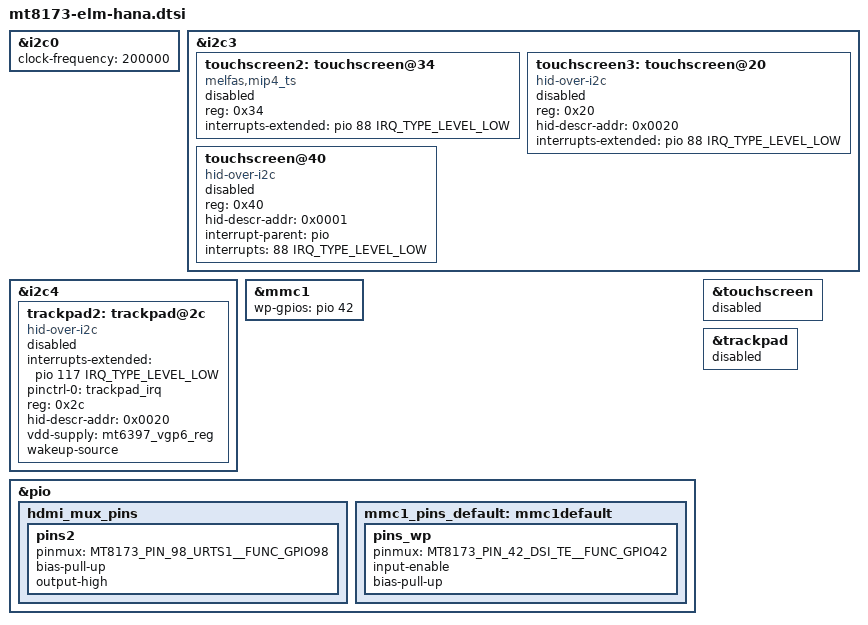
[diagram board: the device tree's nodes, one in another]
// SPDX-License-Identifier: GPL-2.0-only
/*
 * Copyright 2016 MediaTek Inc.
 */

#include "mt8173-elm.dtsi"

&i2c0 {
	clock-frequency = <200000>;
};

&i2c3 {
	touchscreen2: touchscreen@34 {
		compatible = "melfas,mip4_ts";
		reg = <0x34>;
		interrupts-extended = <&pio 88 IRQ_TYPE_LEVEL_LOW>;
		status = "fail-needs-probe";
	};

	/*
	 * Lenovo 100e Chromebook 2nd Gen (MTK) and Lenovo 300e Chromebook 2nd
	 * Gen (MTK) are using synaptics touchscreen (hid-over-i2c driver) as a
	 * second source touchscreen.
	 */
	touchscreen3: touchscreen@20 {
		compatible = "hid-over-i2c";
		reg = <0x20>;
		hid-descr-addr = <0x0020>;
		interrupts-extended = <&pio 88 IRQ_TYPE_LEVEL_LOW>;
		status = "fail-needs-probe";
	};

	/* Lenovo Ideapad C330 uses G2Touch touchscreen as a 2nd source touchscreen */
	touchscreen@40 {
		compatible = "hid-over-i2c";
		reg = <0x40>;
		hid-descr-addr = <0x0001>;
		interrupt-parent = <&pio>;
		interrupts = <88 IRQ_TYPE_LEVEL_LOW>;
		status = "fail-needs-probe";
	};
};

&i2c4 {
	/*
	 * Lenovo 100e Chromebook 2nd Gen (MTK) and Lenovo 300e Chromebook 2nd
	 * Gen (MTK) are using synaptics trackpad (hid-over-i2c driver) as a
	 * second source trackpad.
	 */
	trackpad2: trackpad@2c {
		compatible = "hid-over-i2c";
		interrupts-extended = <&pio 117 IRQ_TYPE_LEVEL_LOW>;
		pinctrl-names = "default";
		pinctrl-0 = <&trackpad_irq>;
		reg = <0x2c>;
		hid-descr-addr = <0x0020>;
		/*
		 * The trackpad needs a post-power-on delay of 100ms,
		 * but at time of writing, the power supply for it on
		 * this board is always on. The delay is therefore not
		 * added to avoid impacting the readiness of the
		 * trackpad.
		 */
		vdd-supply = <&mt6397_vgp6_reg>;
		wakeup-source;
		status = "fail-needs-probe";
	};
};

&mmc1 {
	wp-gpios = <&pio 42 GPIO_ACTIVE_HIGH>;
};

&pio {
	hdmi_mux_pins: hdmi_mux_pins {
		pins2 {
			pinmux = <MT8173_PIN_98_URTS1__FUNC_GPIO98>;
			bias-pull-up;
			output-high;
		};
	};

	mmc1_pins_default: mmc1default {
		pins_wp {
			pinmux = <MT8173_PIN_42_DSI_TE__FUNC_GPIO42>;
			input-enable;
			bias-pull-up;
		};
	};
};

&touchscreen {
	status = "fail-needs-probe";
};

&trackpad {
	status = "fail-needs-probe";
};
